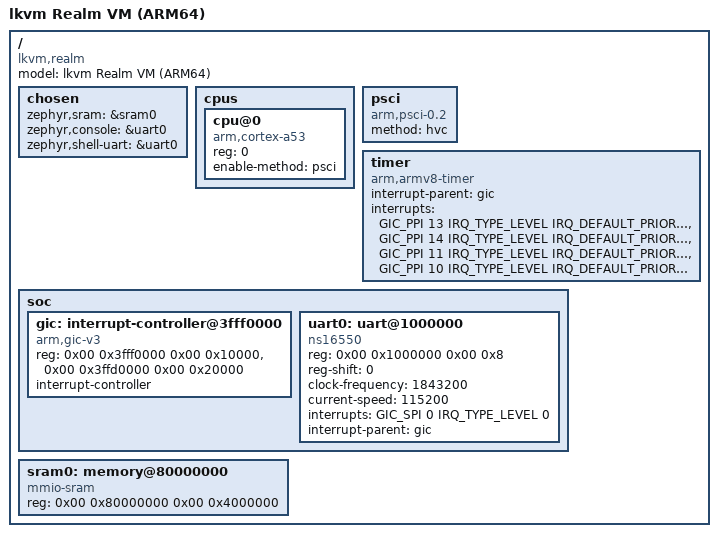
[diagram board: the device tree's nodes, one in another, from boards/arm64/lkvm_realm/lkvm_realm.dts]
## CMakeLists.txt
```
cmake_minimum_required(VERSION 3.20.0)

# Board search path: local boards/ directory
list(APPEND BOARD_ROOT ${CMAKE_CURRENT_SOURCE_DIR})
list(APPEND SOC_ROOT ${CMAKE_CURRENT_SOURCE_DIR})

find_package(Zephyr REQUIRED HINTS $ENV{ZEPHYR_BASE})

project(vecu_zephyr_realm)

zephyr_linker_sources(SECTIONS realm_payload_entry.ld)

target_sources(app PRIVATE
    src/payload_entry.S
    src/payload_mmu.c
    src/rsi.c
    src/rsi_asm.S
    src/main.c
)

if(CONFIG_SERIAL)
    target_sources(app PRIVATE src/realm_uart.c)
endif()

if(DEFINED REALM_MINI_SHELL AND REALM_MINI_SHELL)
    target_compile_definitions(app PRIVATE REALM_MINI_SHELL=1)
    target_sources(app PRIVATE src/realm_timer.c)
endif()

target_link_options(app PRIVATE
    "-Wl,-e,realm_payload_entry"
)
```

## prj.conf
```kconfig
# Console output
CONFIG_PRINTK=y
CONFIG_EARLY_CONSOLE=y
CONFIG_UART_CONSOLE=y

# Stack size
CONFIG_MAIN_STACK_SIZE=4096

# Disable unused subsystems
CONFIG_NETWORKING=n
CONFIG_NET_IPV4=n
CONFIG_NET_IPV6=n
CONFIG_POSIX_API=n
```

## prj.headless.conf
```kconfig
# Headless Realm bring-up overlay
#
# Use the shared status page to prove Zephyr app execution first, without
# depending on early UART/console device init in PRE_KERNEL_1.

CONFIG_EARLY_CONSOLE=n
CONFIG_UART_CONSOLE=n
CONFIG_CONSOLE=n
CONFIG_SERIAL=n
CONFIG_BOOT_BANNER=n

# Keep printk compiled so existing app code does not need to change. There is
# simply no early console backend in this mode.
CONFIG_PRINTK=y
```

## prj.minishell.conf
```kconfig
# Realm mini-shell overlay
#
# Keep the proven headless/main bring-up path, but expose a polling UART
# command loop from the payload app after main() starts.

CONFIG_EARLY_CONSOLE=n
CONFIG_UART_CONSOLE=n
CONFIG_CONSOLE=n
CONFIG_SERIAL=n
CONFIG_BOOT_BANNER=n

# Keep printk compiled so existing code can stay unchanged even though the
# mini shell writes directly to the Realm-safe UART MMIO path.
CONFIG_PRINTK=y

# Shell core runs over the app-owned UART loop via dummy backend.
CONFIG_SYS_CLOCK_EXISTS=y
CONFIG_ARM_ARCH_TIMER=n
CONFIG_SHELL_BACKEND_SERIAL=n

# Enable Zephyr shell core, but keep transport under application control.
# Commands are executed through the dummy backend and the output is forwarded
# over the proven polling UART mini transport in main().
CONFIG_SHELL=y
CONFIG_SHELL_MINIMAL=y
CONFIG_SHELL_BACKEND_DUMMY=y
CONFIG_SHELL_PROMPT_DUMMY=""
CONFIG_SHELL_BACKEND_DUMMY_BUF_SIZE=512
CONFIG_SHELL_CMD_BUFF_SIZE=128
CONFIG_SHELL_PRINTF_BUFF_SIZE=128
CONFIG_SHELL_CMDS=y
CONFIG_SHELL_HELP=y
CONFIG_SHELL_TAB=n
CONFIG_SHELL_HISTORY=n
CONFIG_SHELL_VT100_COMMANDS=n
CONFIG_SHELL_LOG_BACKEND=n
```

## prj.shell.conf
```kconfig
# Realm shell overlay
#
# Keep the standalone shim / unmodified Zephyr payload model, but restore an
# interactive UART path using an out-of-tree polling UART driver that accepts
# the shared-alias MMIO address directly.

CONFIG_EARLY_CONSOLE=n
CONFIG_BOOT_BANNER=n

CONFIG_SYS_CLOCK_EXISTS=y
CONFIG_ARM_ARCH_TIMER=y

CONFIG_PRINTK=y
CONFIG_CONSOLE=n
CONFIG_UART_CONSOLE=n
CONFIG_SERIAL=y

CONFIG_SHELL=y
CONFIG_SHELL_MINIMAL=y
CONFIG_SHELL_BACKEND_SERIAL=y
CONFIG_SHELL_BACKEND_SERIAL_INTERRUPT_DRIVEN=n
CONFIG_SHELL_BACKEND_SERIAL_RX_POLL_PERIOD=10
CONFIG_SHELL_PROMPT_UART="realm:~$ "
CONFIG_SHELL_STACK_SIZE=4096
CONFIG_SHELL_CMD_BUFF_SIZE=128
CONFIG_KERNEL_SHELL=n
CONFIG_DEVICE_SHELL=n
CONFIG_DEVMEM_SHELL=n
```

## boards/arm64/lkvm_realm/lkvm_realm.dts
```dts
/dts-v1/;

#include <mem.h>
#include <arm64/armv8-a.dtsi>
#include <zephyr/dt-bindings/interrupt-controller/arm-gic.h>

/ {
	#address-cells = <2>;
	#size-cells = <2>;
	compatible = "lkvm,realm";
	model = "lkvm Realm VM (ARM64)";

	chosen {
		zephyr,sram = &sram0;
		zephyr,console = &uart0;
		zephyr,shell-uart = &uart0;
	};

	cpus {
		#address-cells = <1>;
		#size-cells = <0>;
		cpu@0 {
			device_type = "cpu";
			compatible = "arm,cortex-a53";
			reg = <0>;
			enable-method = "psci";
		};
	};

	psci {
		compatible = "arm,psci-0.2";
		method = "hvc";
	};

	timer {
		compatible = "arm,armv8-timer";
		interrupt-parent = <&gic>;
		interrupts = <GIC_PPI 13 IRQ_TYPE_LEVEL IRQ_DEFAULT_PRIORITY>,
			     <GIC_PPI 14 IRQ_TYPE_LEVEL IRQ_DEFAULT_PRIORITY>,
			     <GIC_PPI 11 IRQ_TYPE_LEVEL IRQ_DEFAULT_PRIORITY>,
			     <GIC_PPI 10 IRQ_TYPE_LEVEL IRQ_DEFAULT_PRIORITY>;
	};

	soc {
		#address-cells = <2>;
		#size-cells = <2>;
		ranges;

		/* GICv3 - driver compiled for ISR wrapper symbols, init has timeout for Realm */
		gic: interrupt-controller@3fff0000 {
			compatible = "arm,gic-v3", "arm,gic";
			reg = <0x00 0x3fff0000 0x00 0x10000>,
			      <0x00 0x3ffd0000 0x00 0x20000>;
			interrupt-controller;
			#interrupt-cells = <4>;
			#address-cells = <2>;
			#size-cells = <2>;
			status = "okay";
		};

		/* NS16550 UART at 0x1000000 - polling mode (UART_INTERRUPT_DRIVEN=n) */
		uart0: uart@1000000 {
			compatible = "ns16550";
			reg = <0x00 0x1000000 0x00 0x8>;
			reg-shift = <0>;
			clock-frequency = <1843200>;
			current-speed = <115200>;
			interrupts = <GIC_SPI 0 IRQ_TYPE_LEVEL 0>;
			interrupt-parent = <&gic>;
			status = "okay";
		};
	};

	/* Zephyr ARM64 generates an ARM64 image header with text_offset=0.
	 * lkvm reads the header → loads at ram_base + 0 = 0x80000000.
	 * Zephyr must link at 0x80000000 to match. */
	sram0: memory@80000000 {
		compatible = "mmio-sram";
		reg = <0x00 0x80000000 0x00 0x4000000>; /* 64MB */
	};
};
```

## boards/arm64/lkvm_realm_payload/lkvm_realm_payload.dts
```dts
/dts-v1/;

#include <mem.h>
#include <arm64/armv8-a.dtsi>
#include <zephyr/dt-bindings/interrupt-controller/arm-gic.h>

/ {
	#address-cells = <2>;
	#size-cells = <2>;
	compatible = "lkvm,realm-payload";
	model = "lkvm Realm payload VM (ARM64)";

	chosen {
		zephyr,sram = &sram0;
		zephyr,console = &uart0;
		zephyr,shell-uart = &uart0;
	};

	cpus {
		#address-cells = <1>;
		#size-cells = <0>;
		cpu@0 {
			device_type = "cpu";
			compatible = "arm,cortex-a53";
			reg = <0>;
			enable-method = "psci";
		};
	};

	psci {
		compatible = "arm,psci-0.2";
		method = "smc";
	};

	timer {
		compatible = "arm,armv8-timer";
		interrupt-parent = <&gic>;
		interrupts = <GIC_PPI 13 IRQ_TYPE_LEVEL IRQ_DEFAULT_PRIORITY>,
			     <GIC_PPI 14 IRQ_TYPE_LEVEL IRQ_DEFAULT_PRIORITY>,
			     <GIC_PPI 11 IRQ_TYPE_LEVEL IRQ_DEFAULT_PRIORITY>,
			     <GIC_PPI 10 IRQ_TYPE_LEVEL IRQ_DEFAULT_PRIORITY>;
	};

	soc {
		#address-cells = <2>;
		#size-cells = <2>;
		ranges;

		gic: interrupt-controller@13fff0000 {
			compatible = "arm,gic-v3", "arm,gic";
			reg = <0x01 0x3fff0000 0x00 0x10000>,
			      <0x01 0x3ffd0000 0x00 0x20000>;
			interrupt-controller;
			#interrupt-cells = <4>;
			#address-cells = <2>;
			#size-cells = <2>;
			status = "okay";
		};

		uart0: uart@101000000 {
			compatible = "lkvm,realm-uart";
			reg = <0x01 0x1000000 0x00 0x8>;
			reg-shift = <0>;
			clock-frequency = <1843200>;
			current-speed = <115200>;
			status = "okay";
		};
	};

	/*
	 * The standalone Realm shim occupies the first 2 MiB of RAM at
	 * 0x80000000. The Zephyr payload is linked and loaded at 0x80200000.
	 */
	sram0: memory@80200000 {
		compatible = "mmio-sram";
		reg = <0x00 0x80200000 0x00 0x3e00000>;
	};
};
```

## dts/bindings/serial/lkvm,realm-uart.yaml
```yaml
description: Realm-safe polling UART backed by shared-alias NS16550 MMIO

compatible: "lkvm,realm-uart"

include: uart-controller.yaml

properties:
  reg:
    required: true

  reg-shift:
    type: int
    default: 0
    description: Quantity to shift register offsets by.

  current-speed:
    type: int
    default: 115200
    description: Initial baud rate used by the Realm UART driver.

  clock-frequency:
    type: int
    default: 1843200
    description: Input clock used to compute the UART divisor latch.
```

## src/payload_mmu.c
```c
#include <zephyr/arch/arm64/arm_mmu.h>
#include <zephyr/arch/cpu.h>
#include <zephyr/cache.h>
#include <zephyr/devicetree.h>
#include <zephyr/sys/barrier.h>
#include <zephyr/sys/util.h>
#include <stdint.h>
#include <stdbool.h>

#define REALM_STATUS_MAGIC 0x524d5354UL

#define REALM_PAYLOAD_PHASE_NEW_TABLE_DONE      0x28U
#define REALM_PAYLOAD_PHASE_ZEPHYR_RANGES_DONE  0x29U
#define REALM_PAYLOAD_PHASE_DEVICE_RANGES_DONE  0x2aU
#define REALM_PAYLOAD_PHASE_MMU_SYNC_DONE       0x2bU
#define REALM_PAYLOAD_PHASE_ZEPHYR_RANGE_MAP    0x2cU
#define REALM_PAYLOAD_PHASE_DEVICE_RANGE_MAP    0x2dU
#define REALM_PAYLOAD_PHASE_ZEPHYR_RANGE_CHUNK  0x2eU
#define REALM_PAYLOAD_PHASE_SCRATCH_MAP_BEFORE  0x2fU
#define REALM_PAYLOAD_PHASE_SCRATCH_MAP_AFTER   0x30U
#define REALM_PAYLOAD_PHASE_STATUS_MAP_BEFORE   0x31U
#define REALM_PAYLOAD_PHASE_STATUS_MAP_AFTER    0x32U
#define REALM_PAYLOAD_PHASE_FINAL_MAIR_BEFORE   0x34U
#define REALM_PAYLOAD_PHASE_FINAL_MAIR_AFTER    0x35U
#define REALM_PAYLOAD_PHASE_FINAL_TCR_AFTER     0x36U
#define REALM_PAYLOAD_PHASE_FINAL_TTBR0_AFTER   0x37U
#define REALM_PAYLOAD_PHASE_FINAL_SCTLR_BEFORE  0x38U
#define REALM_PAYLOAD_PHASE_FINAL_SCTLR_AFTER   0x39U
#define REALM_PAYLOAD_PHASE_FINAL_ISB_AFTER     0x3aU
#define REALM_PAYLOAD_PHASE_UART_ALIAS_MAP_BEFORE 0x7cU
#define REALM_PAYLOAD_PHASE_UART_ALIAS_MAP_AFTER  0x7dU

/*
 * Runtime decoding of Zephyr's MMU helper layout.
 *
 * Hardcoding BL offsets repeatedly regressed whenever the payload ELF changed
 * between headless, shell, and mini-shell builds. Keep the kernel_ptables
 * decode fixed for now, but discover the BL targets by scanning the current
 * z_arm64_mm_init() body:
 *   1st BL -> new_table()
 *   2nd BL -> __add_map.constprop.0()
 *   3rd BL -> invalidate_tlb_all()
 */
#define REALM_MMU_CALL_SCAN_LIMIT           0x180UL
#define REALM_MMU_KERNEL_PTABLES_ADRP_OFFSET 0x014UL
#define REALM_MMU_KERNEL_PTABLES_LDR_OFFSET  0x044UL
#define REALM_MMU_SCRATCH_PAGE            0x80400000UL
#define REALM_MMU_UART_ALIAS_BASE         DT_REG_ADDR(DT_NODELABEL(uart0))
#define REALM_MMU_UART_ALIAS_SIZE         0x1000UL
#define REALM_MMU_SHARED_MEM_BASE         0x83ffe000UL
#define REALM_MMU_SHARED_MEM_SIZE         0x2000UL
#define REALM_MMU_DEVICE_ATTRS            (MT_DEVICE_nGnRnE | MT_P_RW_U_NA | \
					   MT_DEFAULT_SECURE_STATE)
#define REALM_MMU_SHARED_ATTRS            (MT_NORMAL | MT_P_RW_U_NA | MT_NS)

struct realm_status_page {
	uint32_t magic;
	uint32_t phase;
	uint32_t heartbeat;
	uint32_t reserved;
	uint64_t value0;
	uint64_t value1;
	char text[64];
};

struct realm_payload_flat_range {
	uintptr_t start;
	uintptr_t end;
	uint32_t attrs;
};

extern char _image_ram_start[];
extern char _image_ram_end[];
extern char __bss_start[];
extern char __text_region_start[];
extern char __text_region_end[];
extern char __rodata_region_start[];
extern char __rodata_region_end[];

extern const struct arm_mmu_config mmu_config;
extern void z_arm64_mm_init(bool is_primary_core);
extern uintptr_t realm_payload_shared_alias_bit;

typedef uint64_t *(*realm_new_table_fn_t)(void);
typedef int (*realm_add_map_fn_t)(uintptr_t phys, uintptr_t virt, size_t size,
				  uint32_t attrs);
typedef void (*realm_invalidate_tlb_all_fn_t)(void);

static inline uint32_t realm_read_insn(uintptr_t addr)
{
	return *(const uint32_t *)addr;
}

static inline uintptr_t realm_decode_bl_target(uintptr_t insn_addr, uint32_t insn)
{
	int32_t imm26 = (int32_t)(insn & 0x03ffffffU);

	if ((imm26 & BIT(25)) != 0) {
		imm26 |= ~0x03ffffff;
	}

	return insn_addr + ((intptr_t)imm26 << 2);
}

static inline uintptr_t realm_decode_adrp_target(uintptr_t insn_addr, uint32_t insn)
{
	int64_t immhi = (int64_t)((insn >> 5) & 0x7ffffU);
	int64_t immlo = (int64_t)((insn >> 29) & 0x3U);
	int64_t imm = (immhi << 2) | immlo;

	if ((imm & BIT64(20)) != 0) {
		imm |= ~((1LL << 21) - 1);
	}

	return (insn_addr & ~0xfffUL) + ((uintptr_t)imm << 12);
}

static inline uintptr_t realm_decode_ldr_uimm64_offset(uint32_t insn)
{
	return (uintptr_t)(((insn >> 10) & 0x0fffU) << 3);
}

static inline bool realm_is_bl(uint32_t insn)
{
	return (insn & 0xfc000000U) == 0x94000000U;
}

static inline uintptr_t realm_find_bl_target(uintptr_t start, size_t scan_limit,
					     unsigned int ordinal)
{
	size_t off;
	unsigned int seen = 0U;

	for (off = 0U; off < scan_limit; off += sizeof(uint32_t)) {
		uintptr_t insn_addr = start + off;
		uint32_t insn = realm_read_insn(insn_addr);

		if (!realm_is_bl(insn)) {
			continue;
		}

		if (seen == ordinal) {
			return realm_decode_bl_target(insn_addr, insn);
		}

		seen++;
	}

	return 0U;
}

static inline realm_new_table_fn_t realm_new_table_fn(void)
{
	return (realm_new_table_fn_t)realm_find_bl_target(
		(uintptr_t)z_arm64_mm_init, REALM_MMU_CALL_SCAN_LIMIT, 0U);
}

static inline realm_add_map_fn_t realm_add_map_fn(void)
{
	return (realm_add_map_fn_t)realm_find_bl_target(
		(uintptr_t)z_arm64_mm_init, REALM_MMU_CALL_SCAN_LIMIT, 1U);
}

static inline realm_invalidate_tlb_all_fn_t realm_invalidate_tlb_all_fn(void)
{
	return (realm_invalidate_tlb_all_fn_t)realm_find_bl_target(
		(uintptr_t)z_arm64_mm_init, REALM_MMU_CALL_SCAN_LIMIT, 2U);
}

static inline struct arm_mmu_ptables *realm_kernel_ptables(void)
{
	uintptr_t adrp_addr = (uintptr_t)z_arm64_mm_init +
			      REALM_MMU_KERNEL_PTABLES_ADRP_OFFSET;
	uintptr_t ldr_addr = (uintptr_t)z_arm64_mm_init +
			     REALM_MMU_KERNEL_PTABLES_LDR_OFFSET;
	uintptr_t page_base = realm_decode_adrp_target(adrp_addr,
						       realm_read_insn(adrp_addr));
	uintptr_t ldr_off = realm_decode_ldr_uimm64_offset(
		realm_read_insn(ldr_addr));

	return (struct arm_mmu_ptables *)(page_base + ldr_off);
}

static inline void realm_publish_status(volatile struct realm_status_page *page,
					uint32_t phase, uint64_t value0,
					uint64_t value1, const char *text)
{
	size_t i;

	if (page == NULL) {
		return;
	}

	page->magic = REALM_STATUS_MAGIC;
	page->phase = phase;
	page->value0 = value0;
	page->value1 = value1;

	for (i = 0; i < sizeof(page->text); i++) {
		page->text[i] = '\0';
	}

	if (text != NULL) {
		for (i = 0; i < sizeof(page->text) - 1 && text[i] != '\0'; i++) {
			page->text[i] = text[i];
		}
	}
}

static inline void realm_inv_dcache_after_map(uintptr_t virt, size_t size,
					      uint32_t attrs)
{
	if ((attrs & MT_RW) != MT_RW) {
		return;
	}

	if (MT_TYPE(attrs) == MT_NORMAL || MT_TYPE(attrs) == MT_NORMAL_WT) {
		sys_cache_data_invd_range((void *)virt, size);
	}
}

static inline uint64_t realm_tcr_ps_bits(void)
{
#if defined(CONFIG_ARM64_PA_BITS_48)
	return TCR_PS_BITS_256TB;
#elif defined(CONFIG_ARM64_PA_BITS_44)
	return TCR_PS_BITS_16TB;
#elif defined(CONFIG_ARM64_PA_BITS_42)
	return TCR_PS_BITS_4TB;
#elif defined(CONFIG_ARM64_PA_BITS_40)
	return TCR_PS_BITS_1TB;
#elif defined(CONFIG_ARM64_PA_BITS_36)
	return TCR_PS_BITS_64GB;
#else
	return TCR_PS_BITS_4GB;
#endif
}

static inline uint64_t realm_tcr_el1_value(void)
{
	uint64_t tcr = realm_tcr_ps_bits() << TCR_EL1_IPS_SHIFT;

	tcr |= TCR_EPD1_DISABLE;
	tcr |= TCR_T0SZ(CONFIG_ARM64_VA_BITS);
	tcr |= TCR_TG1_4K | TCR_TG0_4K | TCR_SHARED_INNER |
	       TCR_ORGN_WBWA | TCR_IRGN_WBWA;

	return tcr;
}

void realm_payload_mmu_probe(uintptr_t status_shared_addr)
{
	volatile struct realm_status_page *page =
		(volatile struct realm_status_page *)status_shared_addr;
	struct arm_mmu_ptables *ptables = realm_kernel_ptables();
	realm_new_table_fn_t new_table = realm_new_table_fn();
	realm_add_map_fn_t add_map = realm_add_map_fn();
	realm_invalidate_tlb_all_fn_t invalidate_tlb_all =
		realm_invalidate_tlb_all_fn();
	static const struct realm_payload_flat_range zephyr_ranges[] = {
		{
			.start = (uintptr_t)__rodata_region_start,
			.end = (uintptr_t)__rodata_region_end,
			/*
			 * Diagnostic step: treat the rodata window as RW for now.
			 * The first and second rodata pages both stall when mapped
			 * with RO permissions, so use writable permissions to check
			 * whether the remaining blocker is permission-specific or
			 * address/range-specific.
			 */
			.attrs = MT_NORMAL | MT_P_RW_U_NA |
				 MT_DEFAULT_SECURE_STATE,
		},
		{
			.start = (uintptr_t)__rodata_region_end,
			.end = (uintptr_t)_image_ram_end,
			.attrs = MT_NORMAL | MT_P_RW_U_NA |
				 MT_DEFAULT_SECURE_STATE,
		},
		{
			.start = (uintptr_t)__text_region_start,
			.end = (uintptr_t)__text_region_end,
			.attrs = MT_NORMAL | MT_P_RX_U_RX |
				 MT_DEFAULT_SECURE_STATE,
		},
	};
	unsigned int index;
	uint64_t *base;
	uintptr_t current_text_page =
		((uintptr_t)realm_payload_mmu_probe) & ~(CONFIG_MMU_PAGE_SIZE - 1U);
	uintptr_t first_rodata_page =
		zephyr_ranges[0].start & ~(CONFIG_MMU_PAGE_SIZE - 1U);
	/*
	 * Keep the scratch-map probe out of the payload image entirely.
	 *
	 * Using `_image_ram_end - PAGE_SIZE` accidentally landed inside
	 * Zephyr's noinit stack region (`z_main_stack` / interrupt stacks),
	 * which made the diagnostic ambiguous. Use a fixed unused RAM page
	 * instead so a stall here really points at the generic add_map path.
	 */
		uintptr_t scratch_page = REALM_MMU_SCRATCH_PAGE;
		int ret;

	base = new_table();
	ptables->base_xlat_table = base;
	realm_publish_status(page, REALM_PAYLOAD_PHASE_NEW_TABLE_DONE,
			     (uint64_t)(uintptr_t)base,
			     (uint64_t)(uintptr_t)ptables, "new_table");
	if (base == NULL) {
		return;
	}

	realm_publish_status(page, REALM_PAYLOAD_PHASE_SCRATCH_MAP_BEFORE,
			     scratch_page, (uint64_t)(uintptr_t)__bss_start,
			     "scratch_map_before");
	(void)add_map(scratch_page, scratch_page, CONFIG_MMU_PAGE_SIZE,
		      MT_NORMAL | MT_P_RW_U_NA | MT_DEFAULT_SECURE_STATE);
	realm_publish_status(page, REALM_PAYLOAD_PHASE_SCRATCH_MAP_AFTER,
			     scratch_page, (uint64_t)(uintptr_t)__bss_start,
			     "scratch_map_after");

	/*
	 * Once the MMU is enabled, the payload stub continues to publish
	 * progress markers through the shared status page pointer passed in
	 * from the shim. Map that shared-alias page into the new page tables
	 * now so later phase writes remain valid after TTBR0/SCTLR update.
	 */
	realm_publish_status(page, REALM_PAYLOAD_PHASE_STATUS_MAP_BEFORE,
			     status_shared_addr, status_shared_addr,
			     "status_map_before");
		(void)add_map(status_shared_addr, status_shared_addr,
			      CONFIG_MMU_PAGE_SIZE,
			      MT_NORMAL | MT_P_RW_U_NA | MT_DEFAULT_SECURE_STATE);
		realm_publish_status(page, REALM_PAYLOAD_PHASE_STATUS_MAP_AFTER,
				     status_shared_addr, status_shared_addr,
				     "status_map_after");

		/*
		 * The mini-shell bypasses the Zephyr UART driver and writes
		 * directly to the Realm shared-alias UART. Make that mapping
		 * explicit here so visibility does not depend on whether the
		 * current Kconfig selected a serial driver-backed DT region.
		 */
		realm_publish_status(page, REALM_PAYLOAD_PHASE_UART_ALIAS_MAP_BEFORE,
				     REALM_MMU_UART_ALIAS_BASE,
				     REALM_MMU_UART_ALIAS_SIZE,
				     "uart_alias_map_before");
		ret = add_map(REALM_MMU_UART_ALIAS_BASE, REALM_MMU_UART_ALIAS_BASE,
			      REALM_MMU_UART_ALIAS_SIZE, REALM_MMU_DEVICE_ATTRS);
		realm_publish_status(page, REALM_PAYLOAD_PHASE_UART_ALIAS_MAP_AFTER,
				     REALM_MMU_UART_ALIAS_BASE,
				     (uint64_t)(uint32_t)ret,
				     "uart_alias_map_after");

		if (realm_payload_shared_alias_bit != 0U) {
			uintptr_t shared_alias_base =
				realm_payload_shared_alias_bit | REALM_MMU_SHARED_MEM_BASE;

			(void)add_map(shared_alias_base, shared_alias_base,
				      REALM_MMU_SHARED_MEM_SIZE,
				      REALM_MMU_SHARED_ATTRS);
		}

		for (index = 0U; index < ARRAY_SIZE(zephyr_ranges); index++) {
		uintptr_t start = zephyr_ranges[index].start;
		size_t size = zephyr_ranges[index].end - start;

		if (size != 0U) {
			realm_publish_status(page, REALM_PAYLOAD_PHASE_ZEPHYR_RANGE_MAP,
					     index, start, "map_zephyr_range");
			if (index == 0U || index == 1U || index == 2U) {
				uintptr_t addr;

				for (addr = start; addr < zephyr_ranges[index].end;
				     addr += CONFIG_MMU_PAGE_SIZE) {
					if (index == 0U && addr == first_rodata_page) {
						continue;
					}
					if (index == 2U && addr == current_text_page) {
						continue;
					}
					realm_publish_status(page,
							     REALM_PAYLOAD_PHASE_ZEPHYR_RANGE_CHUNK,
							     index, addr,
							     "map_zephyr_chunk");
					(void)add_map(addr, addr, CONFIG_MMU_PAGE_SIZE,
						      zephyr_ranges[index].attrs);
				}
				if (index == 2U &&
				    current_text_page >= start &&
				    current_text_page < zephyr_ranges[index].end) {
					realm_publish_status(page,
							     REALM_PAYLOAD_PHASE_ZEPHYR_RANGE_CHUNK,
							     index, current_text_page,
							     "map_zephyr_chunk_current");
					(void)add_map(current_text_page, current_text_page,
						      CONFIG_MMU_PAGE_SIZE,
						      zephyr_ranges[index].attrs);
				}
				if (index == 0U &&
				    first_rodata_page >= start &&
				    first_rodata_page < zephyr_ranges[index].end) {
					realm_publish_status(page,
							     REALM_PAYLOAD_PHASE_ZEPHYR_RANGE_CHUNK,
							     index, first_rodata_page,
							     "map_zephyr_chunk_first_rodata");
					(void)add_map(first_rodata_page, first_rodata_page,
						      CONFIG_MMU_PAGE_SIZE,
						      zephyr_ranges[index].attrs);
				}
			} else {
				(void)add_map(start, start, size,
					      zephyr_ranges[index].attrs);
			}
		}
	}

	realm_publish_status(page, REALM_PAYLOAD_PHASE_ZEPHYR_RANGES_DONE,
			     ARRAY_SIZE(zephyr_ranges),
			     (uint64_t)(uintptr_t)&zephyr_ranges[0],
			     "zephyr_ranges");

	for (index = 0U; index < mmu_config.num_regions; index++) {
		const struct arm_mmu_region *region = &mmu_config.mmu_regions[index];

		if (region->size != 0U || region->attrs != 0U) {
			realm_publish_status(page, REALM_PAYLOAD_PHASE_DEVICE_RANGE_MAP,
					     index, region->base_va,
					     "map_device_range");
			(void)add_map(region->base_pa, region->base_va, region->size,
				      region->attrs | MT_NO_OVERWRITE);
		}
	}

	realm_publish_status(page, REALM_PAYLOAD_PHASE_DEVICE_RANGES_DONE,
			     mmu_config.num_regions,
			     (uint64_t)(uintptr_t)mmu_config.mmu_regions,
			     "device_ranges");

	invalidate_tlb_all();

	for (index = 0U; index < ARRAY_SIZE(zephyr_ranges); index++) {
		uintptr_t start = zephyr_ranges[index].start;
		size_t size = zephyr_ranges[index].end - start;

		realm_inv_dcache_after_map(start, size, zephyr_ranges[index].attrs);
	}

	for (index = 0U; index < mmu_config.num_regions; index++) {
		const struct arm_mmu_region *region = &mmu_config.mmu_regions[index];

		realm_inv_dcache_after_map(region->base_va, region->size,
					   region->attrs);
	}

	realm_publish_status(page, REALM_PAYLOAD_PHASE_MMU_SYNC_DONE,
			     (uint64_t)(uintptr_t)ptables->base_xlat_table,
			     mmu_config.num_regions, "mmu_sync");
}

void realm_payload_enable_mmu_final(uintptr_t status_shared_addr)
{
	volatile struct realm_status_page *page =
		(volatile struct realm_status_page *)status_shared_addr;
	struct arm_mmu_ptables *ptables = realm_kernel_ptables();
	uint64_t tcr = realm_tcr_el1_value();
	uint64_t sctlr;

	realm_publish_status(page, REALM_PAYLOAD_PHASE_FINAL_MAIR_BEFORE,
			     (uint64_t)(uintptr_t)ptables,
			     (uint64_t)(uintptr_t)ptables->base_xlat_table,
			     "final_mair_before");
	write_mair_el1(MEMORY_ATTRIBUTES);

	realm_publish_status(page, REALM_PAYLOAD_PHASE_FINAL_MAIR_AFTER,
			     MEMORY_ATTRIBUTES, 0, "final_mair_after");
	write_tcr_el1(tcr);

	realm_publish_status(page, REALM_PAYLOAD_PHASE_FINAL_TCR_AFTER,
			     tcr, 0, "final_tcr_after");
	write_ttbr0_el1((uint64_t)ptables->base_xlat_table);

	realm_publish_status(page, REALM_PAYLOAD_PHASE_FINAL_TTBR0_AFTER,
			     (uint64_t)(uintptr_t)ptables->base_xlat_table,
			     0, "final_ttbr0_after");
	barrier_isync_fence_full();

	sctlr = read_sctlr_el1();
	realm_publish_status(page, REALM_PAYLOAD_PHASE_FINAL_SCTLR_BEFORE,
			     sctlr, SCTLR_M_BIT | SCTLR_C_BIT,
			     "final_sctlr_before");
	write_sctlr_el1(sctlr | SCTLR_M_BIT | SCTLR_C_BIT);

	realm_publish_status(page, REALM_PAYLOAD_PHASE_FINAL_SCTLR_AFTER,
			     read_sctlr_el1(), 0, "final_sctlr_after");
	barrier_isync_fence_full();

	realm_publish_status(page, REALM_PAYLOAD_PHASE_FINAL_ISB_AFTER,
			     read_sctlr_el1(), 0, "final_isb_after");
}
```

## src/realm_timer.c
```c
#include <zephyr/init.h>
#include <zephyr/kernel.h>
#include <zephyr/drivers/timer/system_timer.h>
#include <zephyr/arch/arm64/timer.h>

/*
 * Lightweight Realm timer for the mini-shell profile.
 *
 * The goal here is not full periodic scheduling accuracy yet; it is to
 * provide just enough clock/cycle plumbing for Zephyr shell core +
 * dummy backend to execute commands synchronously from the app-owned
 * UART loop. Timeouts are left as a no-op until we need richer timer
 * semantics for background services.
 */

void sys_clock_set_timeout(int32_t ticks, bool idle)
{
	ARG_UNUSED(ticks);
	ARG_UNUSED(idle);
}

uint32_t sys_clock_elapsed(void)
{
	return 0U;
}

uint32_t sys_clock_cycle_get_32(void)
{
	return (uint32_t)arm_arch_timer_count();
}

#ifdef CONFIG_TIMER_HAS_64BIT_CYCLE_COUNTER
uint64_t sys_clock_cycle_get_64(void)
{
	return arm_arch_timer_count();
}
#endif

static int sys_clock_driver_init(void)
{
	return 0;
}

SYS_INIT(sys_clock_driver_init, PRE_KERNEL_2, CONFIG_SYSTEM_CLOCK_INIT_PRIORITY);
```

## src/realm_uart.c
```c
#define DT_DRV_COMPAT lkvm_realm_uart

#include <zephyr/device.h>
#include <zephyr/devicetree.h>
#include <zephyr/drivers/uart.h>
#include <zephyr/kernel.h>
#include <zephyr/sys/sys_io.h>
#include <zephyr/sys/util.h>

#define REALM_STATUS_MAGIC 0x524d5354UL
#define REALM_PAYLOAD_PHASE_UART_DRV_INIT_BEFORE 0x69U
#define REALM_PAYLOAD_PHASE_UART_DRV_INIT_AFTER  0x6aU

#define REALM_UART_REG_RBR 0x0
#define REALM_UART_REG_THR 0x0
#define REALM_UART_REG_IER 0x1
#define REALM_UART_REG_FCR 0x2
#define REALM_UART_REG_LCR 0x3
#define REALM_UART_REG_MCR 0x4
#define REALM_UART_REG_LSR 0x5
#define REALM_UART_REG_DLL 0x0
#define REALM_UART_REG_DLM 0x1

#define REALM_UART_LCR_8N1 0x03U
#define REALM_UART_LCR_DLAB BIT(7)

#define REALM_UART_MCR_DTR BIT(0)
#define REALM_UART_MCR_RTS BIT(1)
#define REALM_UART_MCR_OUT2 BIT(3)

#define REALM_UART_FCR_ENABLE BIT(0)
#define REALM_UART_FCR_RXRST BIT(1)
#define REALM_UART_FCR_TXRST BIT(2)

#define REALM_UART_LSR_DR   BIT(0)
#define REALM_UART_LSR_OE   BIT(1)
#define REALM_UART_LSR_PE   BIT(2)
#define REALM_UART_LSR_FE   BIT(3)
#define REALM_UART_LSR_THRE BIT(5)

struct realm_uart_config {
	mem_addr_t base;
	uint32_t clock_frequency;
	uint32_t current_speed;
	uint8_t reg_shift;
};

struct realm_uart_data {
	struct uart_config uart_cfg;
};

struct realm_status_page {
	uint32_t magic;
	uint32_t phase;
	uint32_t heartbeat;
	uint32_t reserved;
	uint64_t value0;
	uint64_t value1;
	char text[64];
};

extern uintptr_t realm_payload_status_shared_addr;

static void realm_uart_publish_status(uint32_t phase, uint64_t value0,
				      uint64_t value1, const char *text)
{
	volatile struct realm_status_page *page;
	size_t i;

	if (realm_payload_status_shared_addr == 0U) {
		return;
	}

	page = (volatile struct realm_status_page *)realm_payload_status_shared_addr;
	page->magic = REALM_STATUS_MAGIC;
	page->phase = phase;
	page->value0 = value0;
	page->value1 = value1;

	for (i = 0; i < sizeof(page->text); i++) {
		page->text[i] = '\0';
	}

	if (text != NULL) {
		for (i = 0; i < sizeof(page->text) - 1 && text[i] != '\0'; i++) {
			page->text[i] = text[i];
		}
	}
}

static inline mem_addr_t realm_uart_reg_addr(const struct realm_uart_config *cfg,
					       uint32_t reg)
{
	return cfg->base + ((mem_addr_t)reg << cfg->reg_shift);
}

static inline uint8_t realm_uart_read8(const struct realm_uart_config *cfg,
					 uint32_t reg)
{
	return sys_read8(realm_uart_reg_addr(cfg, reg));
}

static inline void realm_uart_write8(const struct realm_uart_config *cfg,
					  uint32_t reg, uint8_t val)
{
	sys_write8(val, realm_uart_reg_addr(cfg, reg));
}

static int realm_uart_configure_hw(const struct realm_uart_config *cfg,
				     const struct uart_config *uart_cfg)
{
	uint32_t baudrate;
	uint32_t divisor;
	uint8_t lcr = REALM_UART_LCR_8N1;

	if (uart_cfg->parity != UART_CFG_PARITY_NONE ||
	    uart_cfg->stop_bits != UART_CFG_STOP_BITS_1 ||
	    uart_cfg->data_bits != UART_CFG_DATA_BITS_8 ||
	    uart_cfg->flow_ctrl != UART_CFG_FLOW_CTRL_NONE) {
		return -ENOTSUP;
	}

	baudrate = uart_cfg->baudrate ? uart_cfg->baudrate : cfg->current_speed;
	if (baudrate == 0U || cfg->clock_frequency == 0U) {
		return -EINVAL;
	}

	divisor = cfg->clock_frequency / (16U * baudrate);
	if (divisor == 0U) {
		divisor = 1U;
	}

	realm_uart_write8(cfg, REALM_UART_REG_IER, 0U);
	realm_uart_write8(cfg, REALM_UART_REG_LCR, REALM_UART_LCR_DLAB);
	realm_uart_write8(cfg, REALM_UART_REG_DLL, divisor & 0xffU);
	realm_uart_write8(cfg, REALM_UART_REG_DLM, (divisor >> 8) & 0xffU);
	realm_uart_write8(cfg, REALM_UART_REG_LCR, lcr);
	realm_uart_write8(cfg, REALM_UART_REG_FCR,
			  REALM_UART_FCR_ENABLE | REALM_UART_FCR_RXRST |
				  REALM_UART_FCR_TXRST);
	realm_uart_write8(cfg, REALM_UART_REG_MCR,
			  REALM_UART_MCR_DTR | REALM_UART_MCR_RTS |
				  REALM_UART_MCR_OUT2);

	return 0;
}

static int realm_uart_poll_in(const struct device *dev, unsigned char *c)
{
	const struct realm_uart_config *cfg = dev->config;

	if ((realm_uart_read8(cfg, REALM_UART_REG_LSR) & REALM_UART_LSR_DR) == 0U) {
		return -1;
	}

	*c = realm_uart_read8(cfg, REALM_UART_REG_RBR);
	return 0;
}

static void realm_uart_poll_out(const struct device *dev, unsigned char c)
{
	const struct realm_uart_config *cfg = dev->config;

	while ((realm_uart_read8(cfg, REALM_UART_REG_LSR) & REALM_UART_LSR_THRE) == 0U) {
		/* Busy wait; shell backend uses polling mode in Realm bring-up. */
	}

	realm_uart_write8(cfg, REALM_UART_REG_THR, c);
}

static int realm_uart_err_check(const struct device *dev)
{
	const struct realm_uart_config *cfg = dev->config;
	uint8_t lsr = realm_uart_read8(cfg, REALM_UART_REG_LSR);
	int err = 0;

	if ((lsr & REALM_UART_LSR_OE) != 0U) {
		err |= UART_ERROR_OVERRUN;
	}
	if ((lsr & REALM_UART_LSR_PE) != 0U) {
		err |= UART_ERROR_PARITY;
	}
	if ((lsr & REALM_UART_LSR_FE) != 0U) {
		err |= UART_ERROR_FRAMING;
	}

	return err;
}

#ifdef CONFIG_UART_USE_RUNTIME_CONFIGURE
static int realm_uart_configure(const struct device *dev,
				 const struct uart_config *uart_cfg)
{
	struct realm_uart_data *data = dev->data;
	const struct realm_uart_config *cfg = dev->config;
	int ret;

	ret = realm_uart_configure_hw(cfg, uart_cfg);
	if (ret == 0) {
		data->uart_cfg = *uart_cfg;
	}

	return ret;
}

static int realm_uart_config_get(const struct device *dev,
				   struct uart_config *uart_cfg)
{
	const struct realm_uart_data *data = dev->data;

	*uart_cfg = data->uart_cfg;
	return 0;
}
#endif

static int realm_uart_init(const struct device *dev)
{
	struct realm_uart_data *data = dev->data;
	const struct realm_uart_config *cfg = dev->config;
	struct uart_config uart_cfg = {
		.baudrate = cfg->current_speed,
		.parity = UART_CFG_PARITY_NONE,
		.stop_bits = UART_CFG_STOP_BITS_1,
		.data_bits = UART_CFG_DATA_BITS_8,
		.flow_ctrl = UART_CFG_FLOW_CTRL_NONE,
	};
	/*
	 * Realm shell bring-up is currently blocked in PRE_KERNEL_1 when the
	 * driver programs the UART registers this early. For the polling shell
	 * path, the emulated UART is already usable enough for raw THR/LSR
	 * access, so keep init side-effect free and let later poll_in/poll_out
	 * use the shared-alias MMIO path directly.
	 */
	realm_uart_publish_status(REALM_PAYLOAD_PHASE_UART_DRV_INIT_BEFORE,
				  cfg->base, cfg->current_speed,
				  "uart_drv_init_before");

	data->uart_cfg = uart_cfg;
	realm_uart_publish_status(REALM_PAYLOAD_PHASE_UART_DRV_INIT_AFTER,
				  cfg->base, cfg->current_speed,
				  "uart_drv_init_after");
	return 0;
}

static const struct uart_driver_api realm_uart_driver_api = {
	.poll_in = realm_uart_poll_in,
	.poll_out = realm_uart_poll_out,
	.err_check = realm_uart_err_check,
#ifdef CONFIG_UART_USE_RUNTIME_CONFIGURE
	.configure = realm_uart_configure,
	.config_get = realm_uart_config_get,
#endif
};

#define REALM_UART_INIT(n)                                                     \
	static const struct realm_uart_config realm_uart_cfg_##n = {           \
		.base = DT_INST_REG_ADDR(n),                                   \
		.clock_frequency = DT_INST_PROP_OR(n, clock_frequency, 1843200),\
		.current_speed = DT_INST_PROP_OR(n, current_speed, 115200),    \
		.reg_shift = DT_INST_PROP_OR(n, reg_shift, 0),                 \
	};                                                                   \
	static struct realm_uart_data realm_uart_data_##n;                    \
	DEVICE_DT_INST_DEFINE(n, realm_uart_init, NULL,                       \
			      &realm_uart_data_##n, &realm_uart_cfg_##n,      \
			      PRE_KERNEL_1, CONFIG_SERIAL_INIT_PRIORITY,      \
			      &realm_uart_driver_api)

DT_INST_FOREACH_STATUS_OKAY(REALM_UART_INIT);
```

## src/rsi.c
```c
#define _GNU_SOURCE
#include "rsi.h"
#include <zephyr/kernel.h>
#include <zephyr/arch/arm64/arm-smccc.h>
#include <zephyr/sys/printk.h>
#include <string.h>

/* ------------------------------------------------------------------ */
/* Internal: make a generic RSI call via SMC                           */
/* ------------------------------------------------------------------ */
static inline uint64_t rsi_smc(uint64_t fid,
				uint64_t a1, uint64_t a2, uint64_t a3,
				uint64_t a4, uint64_t a5, uint64_t a6,
				uint64_t a7, uint64_t *res1)
{
	struct arm_smccc_res res;
	arm_smccc_smc(fid, a1, a2, a3, a4, a5, a6, a7, &res);
	if (res1) {
		*res1 = res.a1;
	}
	return res.a0;
}

/* ------------------------------------------------------------------ */
/* RSI_ATTESTATION_TOKEN_INIT: needs x0-x8 (FID + 8 challenge words)  */
/* Implemented in rsi_asm.S as rsi_attest_init_smc()                  */
/* ------------------------------------------------------------------ */
extern uint64_t rsi_attest_init_smc(uint64_t fid,
				    uint64_t token_buf_ipa,
				    uint64_t c0, uint64_t c1, uint64_t c2,
				    uint64_t c3, uint64_t c4, uint64_t c5,
				    uint64_t c6, uint64_t c7);

/* ------------------------------------------------------------------ */
/* Public API                                                          */
/* ------------------------------------------------------------------ */

int rsi_version_check(uint64_t *lower, uint64_t *upper)
{
	struct arm_smccc_res res;
	arm_smccc_smc(RSI_VERSION, RSI_ABI_VERSION, 0, 0, 0, 0, 0, 0, &res);
	if (lower) {
		*lower = res.a1;
	}
	if (upper) {
		*upper = res.a2;
	}
	if (res.a0 != RSI_SUCCESS) {
		printk("[RSI] version check failed: 0x%lx\n",
		       (unsigned long)res.a0);
		return -1;
	}
	printk("[RSI] ABI version OK: lower=0x%lx upper=0x%lx\n",
	       (unsigned long)res.a1, (unsigned long)res.a2);
	return 0;
}

int rsi_ipa_state_set(uint64_t base, uint64_t size, uint64_t state)
{
	uint64_t out_top;
	uint64_t ret = rsi_smc(RSI_IPA_STATE_SET, base, size, state,
			       0, 0, 0, 0, &out_top);
	if (ret != RSI_SUCCESS) {
		printk("[RSI] IPA_STATE_SET failed: base=0x%lx size=0x%lx ret=0x%lx\n",
		       (unsigned long)base, (unsigned long)size, (unsigned long)ret);
		return -1;
	}
	return 0;
}

int rsi_shared_mem_init(void)
{
	uint64_t base = SHARED_MEM_BASE;
	uint64_t size = 2 * RSI_GRANULE_SIZE;

	printk("[RSI] marking shared mem: 0x%lx size=0x%lx\n",
	       (unsigned long)base, (unsigned long)size);
	return rsi_ipa_state_set(base, size, RSI_RIPAS_EMPTY);
}

int rsi_attestation_token_init(uint64_t token_buf_ipa, const uint8_t *challenge)
{
	uint64_t c[8] = {0};

	/* pack 64-byte challenge into 8 little-endian uint64_t */
	for (int i = 0; i < 8; i++) {
		for (int j = 0; j < 8; j++) {
			int idx = i * 8 + j;
			if (idx < RSI_CHALLENGE_SIZE) {
				c[i] |= ((uint64_t)challenge[idx]) << (j * 8);
			}
		}
	}

	uint64_t ret = rsi_attest_init_smc(RSI_ATTESTATION_TOKEN_INIT,
					   token_buf_ipa,
					   c[0], c[1], c[2], c[3],
					   c[4], c[5], c[6], c[7]);
	if (ret != RSI_SUCCESS) {
		printk("[RSI] ATTEST_INIT failed: 0x%lx\n", (unsigned long)ret);
		return -1;
	}
	return 0;
}

int rsi_attestation_token_continue(uint64_t token_buf_ipa, uint64_t *token_size)
{
	uint64_t size;
	uint64_t ret = rsi_smc(RSI_ATTESTATION_TOKEN_CONTINUE,
			       token_buf_ipa, 0, 0, 0, 0, 0, 0, &size);
	if (token_size) {
		*token_size = size;
	}
	/* returns RSI_SUCCESS (done) or RSI_INCOMPLETE (more data) */
	return (int)ret;
}

int rsi_attestation_get_token(const uint8_t *challenge,
			      uint8_t *token_buf, uint64_t buf_size,
			      uint64_t *token_size)
{
	uint64_t size = 0;
	int attempts;

	if (buf_size < RSI_GRANULE_SIZE) {
		printk("[RSI] token buffer too small\n");
		return -1;
	}

	if (rsi_attestation_token_init((uint64_t)(uintptr_t)token_buf, challenge) < 0) {
		return -1;
	}

	for (attempts = 0; attempts < 1024; attempts++) {
		int ret = rsi_attestation_token_continue(
			(uint64_t)(uintptr_t)token_buf, &size);

		if (ret == RSI_SUCCESS) {
			if (size > buf_size) {
				printk("[RSI] token size exceeds buffer: 0x%lx\n",
				       (unsigned long)size);
				return -1;
			}
			break;
		} else if (ret == RSI_INCOMPLETE) {
			continue;
		} else {
			printk("[RSI] ATTEST_CONTINUE error: %d\n", ret);
			return -1;
		}
	}

	if (attempts == 1024) {
		printk("[RSI] ATTEST_CONTINUE timed out\n");
		return -1;
	}

	if (token_size) {
		*token_size = size;
	}
	return 0;
}
```

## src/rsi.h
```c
#ifndef RSI_H
#define RSI_H

#include <stdint.h>
#include <stddef.h>

/* ------------------------------------------------------------------ */
/* RSI Function IDs (ARM CCA RMM Specification v1.0)                  */
/* ------------------------------------------------------------------ */
#define RSI_FID(n)                      (0xC4000000UL | (n))

#define RSI_VERSION                     RSI_FID(0x190)
#define RSI_MEASUREMENT_READ            RSI_FID(0x192)
#define RSI_MEASUREMENT_EXTEND          RSI_FID(0x193)
#define RSI_ATTESTATION_TOKEN_INIT      RSI_FID(0x194)
#define RSI_ATTESTATION_TOKEN_CONTINUE  RSI_FID(0x195)
#define RSI_REALM_CONFIG                RSI_FID(0x196)
#define RSI_IPA_STATE_SET               RSI_FID(0x197)
#define RSI_IPA_STATE_GET               RSI_FID(0x198)
#define RSI_HOST_CALL                   RSI_FID(0x199)

/* ------------------------------------------------------------------ */
/* RSI Return Codes                                                    */
/* ------------------------------------------------------------------ */
#define RSI_SUCCESS        0UL
#define RSI_ERROR_INPUT    1UL
#define RSI_ERROR_STATE    2UL
#define RSI_INCOMPLETE     3UL

/* ------------------------------------------------------------------ */
/* Realm IPA State (RIPAS)                                             */
/* ------------------------------------------------------------------ */
#define RSI_RIPAS_EMPTY  0UL
#define RSI_RIPAS_RAM    1UL

/* ------------------------------------------------------------------ */
/* ABI Version                                                         */
/* ------------------------------------------------------------------ */
#define RSI_ABI_VERSION_MAJOR  1UL
#define RSI_ABI_VERSION_MINOR  0UL
#define RSI_ABI_VERSION        ((RSI_ABI_VERSION_MAJOR << 16) | RSI_ABI_VERSION_MINOR)

/* ------------------------------------------------------------------ */
/* Memory layout constants                                             */
/* Shared memory region: top 8KB of 64MB RAM                         */
/* ------------------------------------------------------------------ */
#define REALM_RAM_BASE       0x80000000UL
#define REALM_RAM_SIZE       (64UL * 1024 * 1024)
#define RSI_GRANULE_SIZE     4096UL

/* Shared memory: last 2 granules of RAM */
#define SHARED_MEM_BASE      (REALM_RAM_BASE + REALM_RAM_SIZE - 2 * RSI_GRANULE_SIZE)
#define ATTEST_TOKEN_BASE    SHARED_MEM_BASE                        /* 4KB: token */
#define COMM_CTRL_BASE       (SHARED_MEM_BASE + RSI_GRANULE_SIZE)   /* 4KB: control */

/* Max attestation token size (one granule) */
#define RSI_ATTEST_TOKEN_MAX_SIZE  RSI_GRANULE_SIZE

/* Challenge size (64 bytes = 512 bits) */
#define RSI_CHALLENGE_SIZE   64

/* ------------------------------------------------------------------ */
/* Communication control block (shared with Normal World)              */
/* ------------------------------------------------------------------ */
#define COMM_MAGIC           0xCCA0CC00UL
#define COMM_HOST_REQ_NORMAL 1U
#define COMM_HOST_MSG_SIZE   128U
#define COMM_HOST_STATUS_OK       0U
#define COMM_HOST_STATUS_NO_TOKEN 2U
#define COMM_HOST_STATUS_AGL_NO_VERIFIER 3U
#define COMM_HOST_STATUS_AGL_VERIFY_FAIL 4U
#define COMM_HOST_STATUS_ERROR    0xffffffffU

typedef struct {
	uint32_t magic;           /* COMM_MAGIC when valid */
	uint32_t token_ready;     /* 1 = attestation token written */
	uint32_t token_size;      /* actual token bytes */
	uint32_t gen_count;       /* number of tokens generated */
	uint64_t gen_time_ns;     /* last generation time (ns) */
	uint8_t  challenge[RSI_CHALLENGE_SIZE];
	uint32_t host_req;        /* COMM_HOST_REQ_* from Realm to Normal World */
	uint32_t host_ack;        /* Normal World echoes host_gen when handled */
	uint32_t host_gen;        /* request generation counter */
	uint32_t host_status;     /* Normal World completion status */
	uint64_t host_arg0;
	uint64_t host_arg1;
	char     host_msg[COMM_HOST_MSG_SIZE];
} comm_ctrl_t;

/* ------------------------------------------------------------------ */
/* API                                                                 */
/* ------------------------------------------------------------------ */
int  rsi_version_check(uint64_t *lower, uint64_t *upper);
int  rsi_ipa_state_set(uint64_t base, uint64_t size, uint64_t state);
int  rsi_shared_mem_init(void);
int  rsi_attestation_token_init(uint64_t token_buf_ipa,
                                const uint8_t *challenge);
int  rsi_attestation_token_continue(uint64_t token_buf_ipa,
                                    uint64_t *token_size);
int  rsi_attestation_get_token(const uint8_t *challenge,
                               uint8_t *token_buf, uint64_t buf_size,
                               uint64_t *token_size);

#endif /* RSI_H */
```
